AUTOSAR XML (schema 4-2-2)
package /ComponentTypes
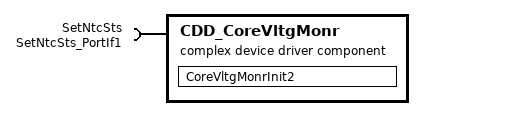
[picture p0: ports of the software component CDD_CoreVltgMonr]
  complex device driver sw component type CDD_CoreVltgMonr
    require port SetNtcSts: client-com-spec=Oper, required-interface=SetNtcSts_PortIf1
    behavior CDD_CoreVltgMonr_InternalBehavior
      ar-typed-per-instance-memorys:
        data CoreVltgMonrStrtUpFltPrmByte: sw-calibration-access=READ-ONLY, type=uint8
      init event CoreVltgMonr_InitEvent: start-on-event=CoreVltgMonrInit2
      runnable CoreVltgMonrInit2
        sync call SC_SetNtcSts_Oper: operation=SetNtcSts.Oper, timeout=0
  swc implementation CDD_CoreVltgMonr_Implementation: behavior=CDD_CoreVltgMonr_InternalBehavior
    code-descriptors:
      code Default: artifact-descriptors=autosar-engineering-object={short-label=Default, category=SWSRC}
